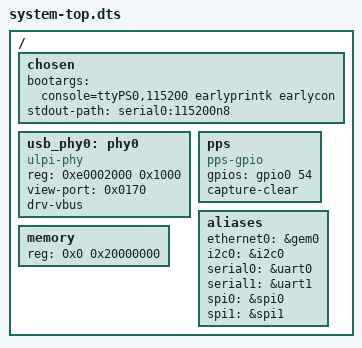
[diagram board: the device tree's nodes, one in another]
/*
 * CAUTION: This file is automatically generated by Xilinx.
 * Version:  
 * Today is: Thu May  4 17:44:19 2023
 */


/dts-v1/;
/include/ "zynq-7000.dtsi"
/include/ "pcw.dtsi"
/ {
	chosen {
		bootargs = "console=ttyPS0,115200 earlyprintk earlycon";
		stdout-path = "serial0:115200n8";
	};
	usb_phy0: phy0 {
		#phy-cells = <0>;
		compatible = "ulpi-phy";
		reg = <0xe0002000 0x1000>;
		view-port = <0x0170>;
		drv-vbus;
	};
	pps {
		compatible = "pps-gpio";
		gpios = <&gpio0 54 0>;
		capture-clear;
	};
	aliases {
		ethernet0 = &gem0;
		i2c0 = &i2c0;
		serial0 = &uart0;
		serial1 = &uart1;
		spi0 = &spi0;
		spi1 = &spi1;
	};
	memory {
		device_type = "memory";
		reg = <0x0 0x20000000>;
	};
};
